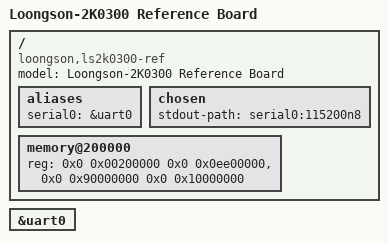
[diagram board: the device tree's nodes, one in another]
// SPDX-License-Identifier: GPL-2.0
/*
 * Copyright (C) 2023 Loongson Technology Corporation Limited
 */

/dts-v1/;

#include "loongson-2k0300.dtsi"

/ {
	compatible = "loongson,ls2k0300-ref", "loongson,ls2k0300";
	model = "Loongson-2K0300 Reference Board";

	aliases {
		serial0 = &uart0;
	};

	chosen {
		stdout-path = "serial0:115200n8";
	};

	memory@200000 {
		device_type = "memory";
		reg = <0x0 0x00200000 0x0 0x0ee00000>,
			  <0x0 0x90000000 0x0 0x10000000>;
	};

};


&uart0 {
	status = "okay";
};

